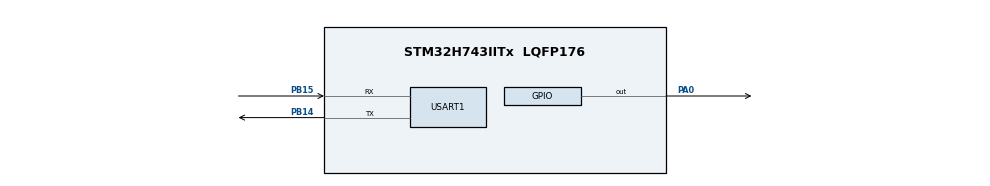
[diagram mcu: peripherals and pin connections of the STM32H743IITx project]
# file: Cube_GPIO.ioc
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CORTEX_M7.default_mode_Activation=1
FREERTOS.Tasks01=defaultTask,24,128,StartDefaultTask,Default,NULL,Dynamic,NULL,NULL
Mcu.Family=STM32H7
Mcu.Name=STM32H743IITx
Mcu.Package=LQFP176
NVIC.PriorityGroup=NVIC_PRIORITYGROUP_4
NVIC.TIM1_UP_IRQn=true\:15\:0\:false\:false\:true\:false\:false\:true\:true
NVIC.TimeBase=TIM1_UP_IRQn
NVIC.TimeBaseIP=TIM1
NVIC.USART1_IRQn=true\:5\:0\:false\:false\:true\:true\:true\:true\:true
PA0.Signal=GPIO_Output
PB14.Mode=Asynchronous
PB14.Signal=USART1_TX
PB15.Mode=Asynchronous
PB15.Signal=USART1_RX
ProjectManager.HeapSize=0x200
ProjectManager.StackSize=0x400
ProjectManager.TargetToolchain=MDK-ARM V5
RCC.ADCFreq_Value=129000000
RCC.APB1Freq_Value=37500000
RCC.APB2Freq_Value=37500000
RCC.APB3Freq_Value=37500000
RCC.APB4Freq_Value=37500000
RCC.CortexFreq_Value=75000000
RCC.D1PPRE=RCC_APB3_DIV2
RCC.D2PPRE1=RCC_APB1_DIV2
RCC.D2PPRE2=RCC_APB2_DIV2
RCC.D3PPRE=RCC_APB4_DIV2
RCC.DIVM1=4
RCC.DIVN1=9
RCC.HCLKFreq_Value=75000000
RCC.PLLFRACN=3072
RCC.SYSCLKFreq_VALUE=75000000
RCC.SYSCLKSource=RCC_SYSCLKSOURCE_PLLCLK
RCC.USBFreq_Value=75000000
USART1.VirtualMode-Asynchronous=VM_ASYNC
VP_FREERTOS_VS_CMSIS_V2.Mode=CMSIS_V2
VP_SYS_VS_tim1.Mode=TIM1
board=custom

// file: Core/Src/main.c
/* USER CODE BEGIN Header */
/**
  ******************************************************************************
  * @file           : main.c
  * @brief          : Main program body
  ******************************************************************************
  * @attention
  *
  * Copyright (c) 2024 STMicroelectronics.
  * All rights reserved.
  *
  * This software is licensed under terms that can be found in the LICENSE file
  * in the root directory of this software component.
  * If no LICENSE file comes with this software, it is provided AS-IS.
  *
  ******************************************************************************
  */
/* USER CODE END Header */
#include "main.h"
#include "cmsis_os.h"
#include "usart.h"
#include "gpio.h"

/* USER CODE BEGIN Includes */
#include "freertos.h"
#include "delay.h"
#include "Emm_V5.h"
/* USER CODE END Includes */

void SystemClock_Config(void);
static void MPU_Config(void);
void MX_FREERTOS_Init(void);

int main(void)
{

  /* MPU Configuration--------------------------------------------------------*/
  MPU_Config();

  /* MCU Configuration--------------------------------------------------------*/

  /* Reset of all peripherals, Initializes the Flash interface and the Systick. */
  HAL_Init();

  /* Configure the system clock */
  SystemClock_Config();

  /* Initialize all configured peripherals */
  MX_GPIO_Init();
  MX_USART1_UART_Init();

  /* Init scheduler */
  osKernelInitialize();

  /* Call init function for freertos objects (in cmsis_os2.c) */
  MX_FREERTOS_Init();

  /* Start scheduler */
  osKernelStart();

  /* We should never get here as control is now taken by the scheduler */

  /* Infinite loop */
  while (1)
  {

  }
}

void SystemClock_Config(void)
{
  RCC_OscInitTypeDef RCC_OscInitStruct = {0};
  RCC_ClkInitTypeDef RCC_ClkInitStruct = {0};

  /** Supply configuration update enable
  */
  HAL_PWREx_ConfigSupply(PWR_LDO_SUPPLY);

  /** Configure the main internal regulator output voltage
  */
  __HAL_PWR_VOLTAGESCALING_CONFIG(PWR_REGULATOR_VOLTAGE_SCALE3);

  while(!__HAL_PWR_GET_FLAG(PWR_FLAG_VOSRDY)) {}

  /** Initializes the RCC Oscillators according to the specified parameters
  * in the RCC_OscInitTypeDef structure.
  */
  RCC_OscInitStruct.OscillatorType = RCC_OSCILLATORTYPE_HSI;
  RCC_OscInitStruct.HSIState = RCC_HSI_DIV1;
  RCC_OscInitStruct.HSICalibrationValue = RCC_HSICALIBRATION_DEFAULT;
  RCC_OscInitStruct.PLL.PLLState = RCC_PLL_ON;
  RCC_OscInitStruct.PLL.PLLSource = RCC_PLLSOURCE_HSI;
  RCC_OscInitStruct.PLL.PLLM = 4;
  RCC_OscInitStruct.PLL.PLLN = 9;
  RCC_OscInitStruct.PLL.PLLP = 2;
  RCC_OscInitStruct.PLL.PLLQ = 2;
  RCC_OscInitStruct.PLL.PLLR = 2;
  RCC_OscInitStruct.PLL.PLLRGE = RCC_PLL1VCIRANGE_3;
  RCC_OscInitStruct.PLL.PLLVCOSEL = RCC_PLL1VCOMEDIUM;
  RCC_OscInitStruct.PLL.PLLFRACN = 3072;
  if (HAL_RCC_OscConfig(&RCC_OscInitStruct) != HAL_OK)
  {
    Error_Handler();
  }

  /** Initializes the CPU, AHB and APB buses clocks
  */
  RCC_ClkInitStruct.ClockType = RCC_CLOCKTYPE_HCLK|RCC_CLOCKTYPE_SYSCLK
                              |RCC_CLOCKTYPE_PCLK1|RCC_CLOCKTYPE_PCLK2
                              |RCC_CLOCKTYPE_D3PCLK1|RCC_CLOCKTYPE_D1PCLK1;
  RCC_ClkInitStruct.SYSCLKSource = RCC_SYSCLKSOURCE_PLLCLK;
  RCC_ClkInitStruct.SYSCLKDivider = RCC_SYSCLK_DIV1;
  RCC_ClkInitStruct.AHBCLKDivider = RCC_HCLK_DIV1;
  RCC_ClkInitStruct.APB3CLKDivider = RCC_APB3_DIV2;
  RCC_ClkInitStruct.APB1CLKDivider = RCC_APB1_DIV2;
  RCC_ClkInitStruct.APB2CLKDivider = RCC_APB2_DIV2;
  RCC_ClkInitStruct.APB4CLKDivider = RCC_APB4_DIV2;

  if (HAL_RCC_ClockConfig(&RCC_ClkInitStruct, FLASH_LATENCY_1) != HAL_OK)
  {
    Error_Handler();
  }
}

 /* MPU Configuration */

void MPU_Config(void)
{
  MPU_Region_InitTypeDef MPU_InitStruct = {0};

  /* Disables the MPU */
  HAL_MPU_Disable();

  /** Initializes and configures the Region and the memory to be protected
  */
  MPU_InitStruct.Enable = MPU_REGION_ENABLE;
  MPU_InitStruct.Number = MPU_REGION_NUMBER0;
  MPU_InitStruct.BaseAddress = 0x0;
  MPU_InitStruct.Size = MPU_REGION_SIZE_4GB;
  MPU_InitStruct.SubRegionDisable = 0x87;
  MPU_InitStruct.TypeExtField = MPU_TEX_LEVEL0;
  MPU_InitStruct.AccessPermission = MPU_REGION_NO_ACCESS;
  MPU_InitStruct.DisableExec = MPU_INSTRUCTION_ACCESS_DISABLE;
  MPU_InitStruct.IsShareable = MPU_ACCESS_SHAREABLE;
  MPU_InitStruct.IsCacheable = MPU_ACCESS_NOT_CACHEABLE;
  MPU_InitStruct.IsBufferable = MPU_ACCESS_NOT_BUFFERABLE;

  HAL_MPU_ConfigRegion(&MPU_InitStruct);
  /* Enables the MPU */
  HAL_MPU_Enable(MPU_PRIVILEGED_DEFAULT);

}

void HAL_TIM_PeriodElapsedCallback(TIM_HandleTypeDef *htim)
{
  if (htim->Instance == TIM1) {
    HAL_IncTick();
  }
}

void Error_Handler(void)
{
  __disable_irq();
  while (1)
  {
  }
}

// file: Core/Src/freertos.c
/* USER CODE BEGIN Header */
/**
  ******************************************************************************
  * File Name          : freertos.c
  * Description        : Code for freertos applications
  ******************************************************************************
  * @attention
  *
  * Copyright (c) 2024 STMicroelectronics.
  * All rights reserved.
  *
  * This software is licensed under terms that can be found in the LICENSE file
  * in the root directory of this software component.
  * If no LICENSE file comes with this software, it is provided AS-IS.
  *
  ******************************************************************************
  */
/* USER CODE END Header */

#include "FreeRTOS.h"
#include "task.h"
#include "main.h"
#include "cmsis_os.h"

/* USER CODE BEGIN PD */
#define START_TASK_PRIO 1
#define START_TASK_STACK_SIZE 128
#define TASK1_PRIO 2
#define TASK1_STACK_SIZE 128
#define TASK2_PRIO 3
#define TASK2_STACK_SIZE 128
#define TASK3_PRIO 4
#define TASK3_STACK_SIZE 128
/* USER CODE END PD */

/* USER CODE BEGIN Variables */
osThreadId_t task1Handle;
const osThreadAttr_t task1_attributes = {
  .name = "task1",
  .stack_size = TASK1_STACK_SIZE * 4,
  .priority = (osPriority_t) TASK1_PRIO,
};

osThreadId_t task2Handle;
const osThreadAttr_t task2_attributes = {
  .name = "task2",
  .stack_size = TASK2_STACK_SIZE * 4,
  .priority = (osPriority_t) TASK2_PRIO,
};

osThreadId_t task3Handle;
const osThreadAttr_t task3_attributes = {
  .name = "task3",
  .stack_size = TASK3_STACK_SIZE * 4,
  .priority = (osPriority_t) TASK3_PRIO,
};
/* USER CODE END Variables */
/* Definitions for defaultTask */
osThreadId_t defaultTaskHandle;
const osThreadAttr_t defaultTask_attributes = {
  .name = "defaultTask",
  .stack_size = 128 * 4,
  .priority = (osPriority_t) osPriorityNormal,
};

/* USER CODE BEGIN FunctionPrototypes */
// 任务1, 2, 3 的定�??
// 线程�??，PA0点灯500ms
void task1(void* pvParameters)
{
  while(1)
  {
    HAL_GPIO_TogglePin(GPIOA, GPIO_PIN_0);
    vTaskDelay(200);
  }
}

// 线程二，PA1点灯200ms
void task2(void* pvParameters)
{
  while(1)
  {
    HAL_GPIO_TogglePin(GPIOA, GPIO_PIN_1);
    vTaskDelay(200);
  }
}

// 线程三，如果PA2被按下，删除task1
void task3(void* pvParameters)
{
  uint32_t button_state = 0;
  uint32_t last_button_state = 0;
  uint32_t last_debounce_time = 0;
  const uint32_t debounce_delay = 50; // 消抖延迟，单位为毫秒

  while(1)
  {
    button_state = HAL_GPIO_ReadPin(GPIOA, GPIO_PIN_2);

    // 如果读取的按键状态与上一次的状�?�不同，重置消抖计时�??
    if (button_state != last_button_state)
    {
      last_debounce_time = xTaskGetTickCount();
    }

    // 如果消抖计时器超过设定的延迟，认为按键状态已稳定
    if ((xTaskGetTickCount() - last_debounce_time) > debounce_delay)
    {
      // 如果按键被按下，并且task1还存在，删除task1
      if(button_state == GPIO_PIN_SET && task1Handle != NULL)
      {
        vTaskDelete(task1Handle);
        task1Handle = NULL;
      }
    }

    last_button_state = button_state;

    vTaskDelay(10);
  }
}
/* USER CODE END FunctionPrototypes */

void StartDefaultTask(void *argument);

void MX_FREERTOS_Init(void); /* (MISRA C 2004 rule 8.1) */

void MX_FREERTOS_Init(void) {

  /* Create the thread(s) */
  /* creation of defaultTask */
  defaultTaskHandle = osThreadNew(StartDefaultTask, NULL, &defaultTask_attributes);

  /* USER CODE BEGIN RTOS_THREADS */
  /* add threads, ... */
  void (*start_tasks[])(void *) = {task1, task2, task3}; // 任务函数数组
  const osThreadAttr_t *task_attributes[] = {&task1_attributes, &task2_attributes, &task3_attributes}; // 任务属�?�数�??
  osThreadId_t *task_handles[] = {&task1Handle, &task2Handle, &task3Handle}; // 任务句柄数组
  for (size_t i = 0; i < sizeof(start_tasks) / sizeof(start_tasks[0]); i++)
  {
       *task_handles[i] = osThreadNew(start_tasks[i], NULL, task_attributes[i]); // 创建3个任务线�??
  }
  /* USER CODE END RTOS_THREADS */

}

void StartDefaultTask(void *argument)
{
  while(1)
  {
    osDelay(1);
  }
}
